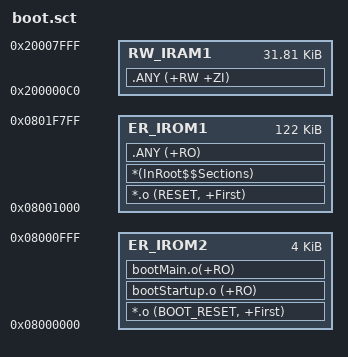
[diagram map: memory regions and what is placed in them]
; *************************************************************
; *** Scatter-Loading Description File generated by uVision ***
; *************************************************************

LR_IROM2 0x08000000 0x00001000  {    ; load region size_region
  ER_IROM2 0x08000000 0x00001000  {  ; load address = execution address
   *.o (BOOT_RESET, +First)
   bootStartup.o (+RO)
   bootMain.o(+RO)
  }
}

LR_IROM1 0x08001000 0x001E800  {    ; load region size_region
  ER_IROM1 0x08001000 0x001E800  {  ; load address = execution address  128K - 1K(boot) - 0.5K(fpe)
   *.o (RESET, +First)
   *(InRoot$$Sections)
   .ANY (+RO)
  }
  RW_IRAM1 0x200000c0 0x00007F40  {  ; RW data
   .ANY (+RW +ZI)
  }
}
